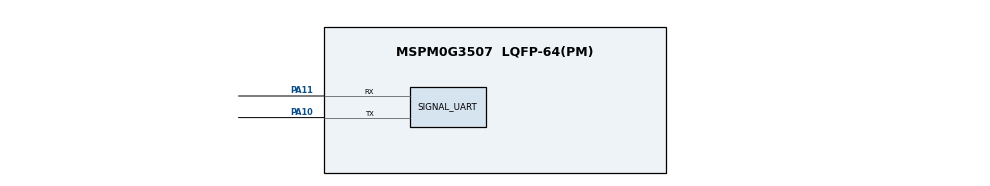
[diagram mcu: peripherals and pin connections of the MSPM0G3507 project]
/** PROFILE_02_DUAL_ADC: synchronized ADC0/ADC1, two DMA channels, UART0. */
//@cliArgs --device "MSPM0G350X" --package "LQFP-64(PM)" --part "Default"
//@v2CliArgs --device "MSPM0G3507" --package "LQFP-64(PM)"
// @cliArgs --board /ti/boards/LP_MSPM0G3507 --rtos nortos

const ProjectConfig = scripting.addModule("/ti/project_config/ProjectConfig");
const Board = scripting.addModule("/ti/driverlib/Board");
const SYSCTL = scripting.addModule("/ti/driverlib/SYSCTL");
const ADC12 = scripting.addModule("/ti/driverlib/ADC12", {}, false);
const ADC_A = ADC12.addInstance();
const ADC_B = ADC12.addInstance();
const TIMER = scripting.addModule("/ti/driverlib/TIMER", {}, false);
const DUAL_TIMER = TIMER.addInstance();
const UART = scripting.addModule("/ti/driverlib/UART", {}, false);
const SIGNAL_UART = UART.addInstance();

ProjectConfig.genLibCMSIS = true;

ADC_A.$name = "SIGNAL_ADC_A";
ADC_A.sampClkSrc = "DL_ADC12_CLOCK_ULPCLK";
ADC_A.adcMem0chansel = "DL_ADC12_INPUT_CHAN_2";
ADC_A.sampleTime0 = "62.5ns";
ADC_A.powerDownMode = "DL_ADC12_POWER_DOWN_MODE_MANUAL";
ADC_A.trigSrc = "DL_ADC12_TRIG_SRC_EVENT";
ADC_A.repeatMode = true;
ADC_A.adcMem0trig = "DL_ADC12_TRIGGER_MODE_TRIGGER_NEXT";
ADC_A.subChanID = 1;
ADC_A.configureDMA = true;
ADC_A.sampCnt = 1;
ADC_A.enabledDMATriggers = ["DL_ADC12_DMA_MEM0_RESULT_LOADED"];
ADC_A.enabledInterrupts = ["DL_ADC12_INTERRUPT_DMA_DONE"];
ADC_A.peripheral.$assign = "ADC0";
ADC_A.peripheral.adcPin2.$assign = "PA25";
ADC_A.DMA_CHANNEL.$name = "SIGNAL_ADC_A_DMA";
ADC_A.DMA_CHANNEL.peripheral.$assign = "DMA_CH0";
ADC_A.DMA_CHANNEL.addressMode = "f2b";
ADC_A.DMA_CHANNEL.srcLength = "HALF_WORD";
ADC_A.DMA_CHANNEL.dstLength = "HALF_WORD";
ADC_A.DMA_CHANNEL.transferMode = "SINGLE";

ADC_B.$name = "SIGNAL_ADC_B";
ADC_B.sampClkSrc = "DL_ADC12_CLOCK_ULPCLK";
ADC_B.adcMem0chansel = "DL_ADC12_INPUT_CHAN_2";
ADC_B.sampleTime0 = "62.5ns";
ADC_B.powerDownMode = "DL_ADC12_POWER_DOWN_MODE_MANUAL";
ADC_B.trigSrc = "DL_ADC12_TRIG_SRC_EVENT";
ADC_B.repeatMode = true;
ADC_B.adcMem0trig = "DL_ADC12_TRIGGER_MODE_TRIGGER_NEXT";
ADC_B.subChanID = 2;
ADC_B.configureDMA = true;
ADC_B.sampCnt = 1;
ADC_B.enabledDMATriggers = ["DL_ADC12_DMA_MEM0_RESULT_LOADED"];
ADC_B.enabledInterrupts = ["DL_ADC12_INTERRUPT_DMA_DONE"];
ADC_B.peripheral.$assign = "ADC1";
ADC_B.peripheral.adcPin2.$assign = "PA17";
ADC_B.DMA_CHANNEL.$name = "SIGNAL_ADC_B_DMA";
ADC_B.DMA_CHANNEL.peripheral.$assign = "DMA_CH1";
ADC_B.DMA_CHANNEL.addressMode = "f2b";
ADC_B.DMA_CHANNEL.srcLength = "HALF_WORD";
ADC_B.DMA_CHANNEL.dstLength = "HALF_WORD";
ADC_B.DMA_CHANNEL.transferMode = "SINGLE";

DUAL_TIMER.$name = "SIGNAL_DUAL_ADC_TIMER";
DUAL_TIMER.timerClkSrc = "BUSCLK";
DUAL_TIMER.timerPeriod = "10us";
DUAL_TIMER.timerMode = "PERIODIC";
DUAL_TIMER.event1PublisherChannel = 1;
DUAL_TIMER.event1ControllerInterruptEn = ["ZERO_EVENT"];
DUAL_TIMER.event2PublisherChannel = 2;
DUAL_TIMER.event2ControllerInterruptEn = ["ZERO_EVENT"];
DUAL_TIMER.peripheral.$assign = "TIMG0";

SIGNAL_UART.$name = "SIGNAL_UART";
SIGNAL_UART.profile = "CONFIG_PROFILE_1";
SIGNAL_UART.peripheral.$assign = "UART0";
SIGNAL_UART.uartClkSrc = "BUSCLK";
SIGNAL_UART.targetBaudRate = 115200;
SIGNAL_UART.enableInternalLoopback = false;
SIGNAL_UART.enableFIFO = true;
SIGNAL_UART.peripheral.txPin.$assign = "PA10";
SIGNAL_UART.peripheral.rxPin.$assign = "PA11";

SYSCTL.forceDefaultClkConfig = true;
SYSCTL.clockTreeEn = true;
